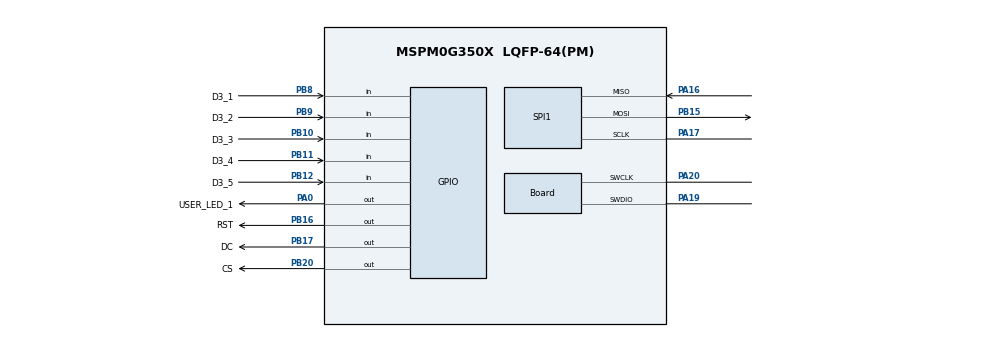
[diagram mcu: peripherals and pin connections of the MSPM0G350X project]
/**
 * @cliArgs --device "MSPM0G350X" --package "LQFP-64(PM)" --part "Default" --product "mspm0_sdk@2.00.01.00"
 * @versions {"tool":"1.20.0+3587"}
 */

/**
 * Import the modules used in this configuration.
 */
const ADC12         = scripting.addModule("/ti/driverlib/ADC12", {}, false);
const ADC121        = ADC12.addInstance();
const Board         = scripting.addModule("/ti/driverlib/Board");
const GPIO          = scripting.addModule("/ti/driverlib/GPIO", {}, false);
const GPIO1         = GPIO.addInstance();
const GPIO2         = GPIO.addInstance();
const GPIO3         = GPIO.addInstance();
const GPIO4         = GPIO.addInstance();
const SPI           = scripting.addModule("/ti/driverlib/SPI", {}, false);
const SPI1          = SPI.addInstance();
const SYSCTL        = scripting.addModule("/ti/driverlib/SYSCTL");
const TIMER         = scripting.addModule("/ti/driverlib/TIMER", {}, false);
const TIMER1        = TIMER.addInstance();
const ProjectConfig = scripting.addModule("/ti/project_config/ProjectConfig");

/**
 * Write custom configuration values to the imported modules.
 */
ADC121.$name                      = "ADC12_0";
ADC121.startAdd                   = 1;
ADC121.adcMem1chansel             = "DL_ADC12_INPUT_CHAN_1";
ADC121.enabledInterrupts          = ["DL_ADC12_INTERRUPT_MEM1_RESULT_LOADED"];
ADC121.interruptPriority          = "3";
ADC121.sampClkSrc                 = "DL_ADC12_CLOCK_ULPCLK";
ADC121.sampleTime0                = "1ms";
ADC121.peripheral.$assign         = "ADC0";
ADC121.peripheral.adcPin1.$assign = "PA26";
ADC121.adcPin1Config.$name        = "ti_driverlib_gpio_GPIOPinGeneric3";

Board.peripheral.$assign          = "DEBUGSS";
Board.peripheral.swclkPin.$assign = "PA20";
Board.peripheral.swdioPin.$assign = "PA19";

GPIO1.port                           = "PORTA";
GPIO1.$name                          = "GPIO_LEDS_PORT";
GPIO1.portSegment                    = "Lower";
GPIO1.associatedPins[0].initialValue = "SET";
GPIO1.associatedPins[0].$name        = "USER_LED_1";
GPIO1.associatedPins[0].assignedPin  = "0";
GPIO1.associatedPins[0].pin.$assign  = "PA0";

GPIO2.$name                         = "GPIO_RGB";
GPIO2.port                          = "PORTB";
GPIO2.portSegment                   = "Upper";
GPIO2.associatedPins.create(3);
GPIO2.associatedPins[0].$name       = "RED";
GPIO2.associatedPins[0].assignedPin = "26";
GPIO2.associatedPins[1].$name       = "GREEN";
GPIO2.associatedPins[1].assignedPin = "27";
GPIO2.associatedPins[2].$name       = "BLUE";
GPIO2.associatedPins[2].assignedPin = "22";

GPIO3.$name                              = "GPIO_KEY";
GPIO3.port                               = "PORTB";
GPIO3.associatedPins.create(8);
GPIO3.associatedPins[0].$name            = "KEY_1";
GPIO3.associatedPins[0].direction        = "INPUT";
GPIO3.associatedPins[0].assignedPin      = "21";
GPIO3.associatedPins[0].internalResistor = "PULL_UP";
GPIO3.associatedPins[1].assignedPin      = "23";
GPIO3.associatedPins[1].$name            = "KEY_2";
GPIO3.associatedPins[1].direction        = "INPUT";
GPIO3.associatedPins[1].internalResistor = "PULL_UP";
GPIO3.associatedPins[2].assignedPin      = "24";
GPIO3.associatedPins[2].$name            = "KEY_3";
GPIO3.associatedPins[2].direction        = "INPUT";
GPIO3.associatedPins[2].internalResistor = "PULL_UP";
GPIO3.associatedPins[3].direction        = "INPUT";
GPIO3.associatedPins[3].$name            = "D3_2";
GPIO3.associatedPins[3].internalResistor = "PULL_UP";
GPIO3.associatedPins[3].pin.$assign      = "PB9";
GPIO3.associatedPins[4].$name            = "D3_1";
GPIO3.associatedPins[4].direction        = "INPUT";
GPIO3.associatedPins[4].internalResistor = "PULL_UP";
GPIO3.associatedPins[4].pin.$assign      = "PB8";
GPIO3.associatedPins[5].$name            = "D3_3";
GPIO3.associatedPins[5].direction        = "INPUT";
GPIO3.associatedPins[5].internalResistor = "PULL_UP";
GPIO3.associatedPins[5].pin.$assign      = "PB10";
GPIO3.associatedPins[6].$name            = "D3_4";
GPIO3.associatedPins[6].direction        = "INPUT";
GPIO3.associatedPins[6].internalResistor = "PULL_UP";
GPIO3.associatedPins[6].pin.$assign      = "PB11";
GPIO3.associatedPins[7].$name            = "D3_5";
GPIO3.associatedPins[7].direction        = "INPUT";
GPIO3.associatedPins[7].internalResistor = "PULL_UP";
GPIO3.associatedPins[7].pin.$assign      = "PB12";

GPIO4.$name                         = "GPIO_OLED";
GPIO4.associatedPins.create(3);
GPIO4.associatedPins[0].$name       = "RST";
GPIO4.associatedPins[0].pin.$assign = "PB16";
GPIO4.associatedPins[1].$name       = "DC";
GPIO4.associatedPins[1].pin.$assign = "PB17";
GPIO4.associatedPins[2].$name       = "CS";
GPIO4.associatedPins[2].pin.$assign = "PB20";

SPI1.$name                      = "SPI_0";
SPI1.targetBitRate              = 1000000;
SPI1.frameFormat                = "MOTO3";
SPI1.polarity                   = "1";
SPI1.phase                      = "1";
SPI1.peripheral.$assign         = "SPI1";
SPI1.peripheral.sclkPin.$assign = "PA17";
SPI1.peripheral.mosiPin.$assign = "PB15";
SPI1.peripheral.misoPin.$assign = "PA16";
SPI1.sclkPinConfig.$name        = "ti_driverlib_gpio_GPIOPinGeneric0";
SPI1.mosiPinConfig.$name        = "ti_driverlib_gpio_GPIOPinGeneric1";
SPI1.misoPinConfig.$name        = "ti_driverlib_gpio_GPIOPinGeneric2";

SYSCTL.clockTreeEn = true;

TIMER1.$name              = "TIMER_0";
TIMER1.interrupts         = ["ZERO"];
TIMER1.timerMode          = "PERIODIC";
TIMER1.timerPeriod        = "1ms";
TIMER1.peripheral.$assign = "TIMG0";

ProjectConfig.switchCondition = false;
ProjectConfig.deviceSpin      = "MSPM0G3507";

/**
 * Pinmux solution for unlocked pins/peripherals. This ensures that minor changes to the automatic solver in a future
 * version of the tool will not impact the pinmux you originally saw.  These lines can be completely deleted in order to
 * re-solve from scratch.
 */
GPIO2.associatedPins[0].pin.$suggestSolution = "PB26";
GPIO2.associatedPins[1].pin.$suggestSolution = "PB27";
GPIO2.associatedPins[2].pin.$suggestSolution = "PB22";
GPIO3.associatedPins[0].pin.$suggestSolution = "PB21";
GPIO3.associatedPins[1].pin.$suggestSolution = "PB23";
GPIO3.associatedPins[2].pin.$suggestSolution = "PB24";
